# f2838x_cpu1_periph_ac_regs register map
Vendor: Texas Instruments
Peripheral module from a debugger description file (folder C2000).
Address unit: 16 bits
Registers are 32-bit, read-write, no defined reset value unless marked. A register's access mark holds for its fields unless they carry their own. Offsets are as the file gives them; lines under a group give offsets from that group; [hi:lo] are bit positions; {n}, {i} and the like mark numbered series; 'fields as' and 'values as' point back to an identical list; <NAME> marks a mode.

## CPU1_PERIPH_AC_REGS — CPU1 PERIPH AC Registers
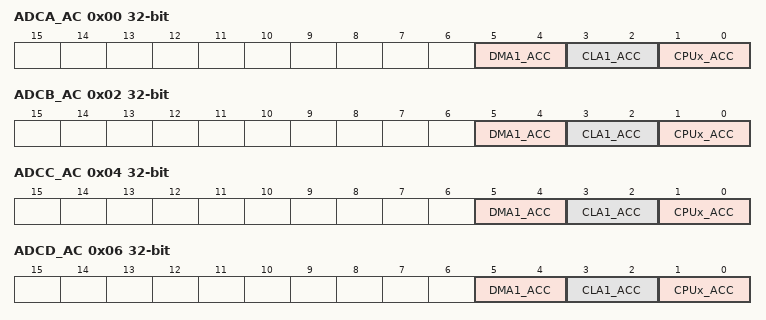
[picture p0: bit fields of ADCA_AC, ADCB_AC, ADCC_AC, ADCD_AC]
0x00 ADCA_AC — ADCA Master Access Control Register
  [5:4] DMA1_ACC — DMA1 Access Conditions to Peripheral
  [3:2] CLA1_ACC — CLA1 Access Conditions to Peripheral
  [1:0] CPUx_ACC — CPU1 Access conditions to peripheral
0x02 ADCB_AC — ADCB Master Access Control Register
  [5:4] DMA1_ACC — DMA1 Access Conditions to Peripheral
  [3:2] CLA1_ACC — CLA1 Access Conditions to Peripheral
  [1:0] CPUx_ACC — CPUx Access conditions to peripheral
0x04 ADCC_AC — ADCC Master Access Control Register
  fields as ADCB_AC
0x06 ADCD_AC — ADCD Master Access Control Register
  fields as ADCB_AC
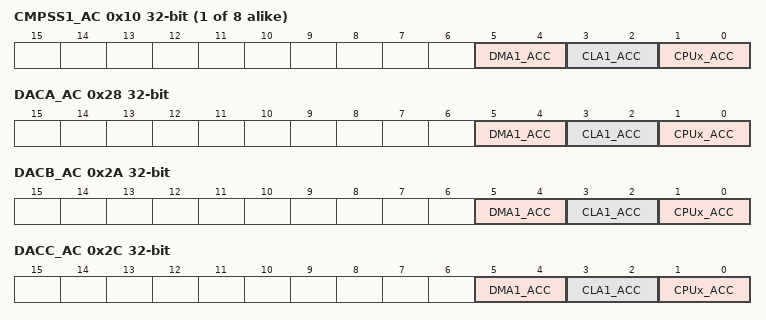
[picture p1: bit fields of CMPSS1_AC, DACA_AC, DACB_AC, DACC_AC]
{0xE+2i} CMPSS{i}_AC (i=1..8) — CMPSS{i} Master Access Control Register
  fields as ADCB_AC
0x28 DACA_AC — DACA Master Access Control Register
  fields as ADCB_AC
0x2A DACB_AC — DACB Master Access Control Register
  fields as ADCB_AC
0x2C DACC_AC — DACC Master Access Control Register
  fields as ADCB_AC
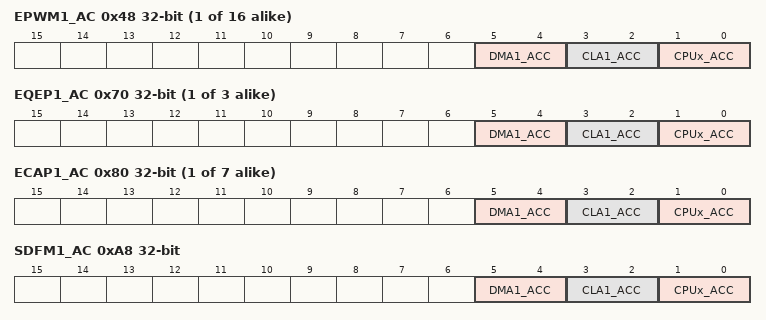
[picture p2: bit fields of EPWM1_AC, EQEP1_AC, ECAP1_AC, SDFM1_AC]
{0x46+2i} EPWM{i}_AC (i=1..16) — EPWM{i} Master Access Control Register
  fields as ADCB_AC
{0x6E+2i} EQEP{i}_AC (i=1..3) — EQEP{i} Master Access Control Register
  fields as ADCB_AC
{0x7E+2i} ECAP{i}_AC (i=1..7) — ECAP{i} Master Access Control Register
  fields as ADCB_AC
0xA8 SDFM1_AC — SDFM1 Master Access Control Register
  fields as ADCB_AC
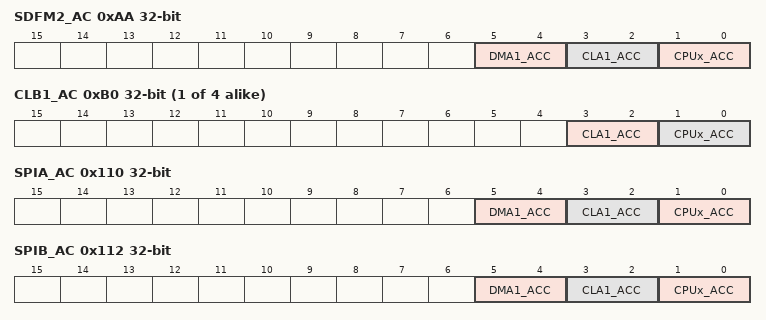
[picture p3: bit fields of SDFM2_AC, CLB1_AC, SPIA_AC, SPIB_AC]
0xAA SDFM2_AC — SDFM2 Master Access Control Register
  fields as ADCB_AC
{0xAE+2i} CLB{i}_AC (i=1..4) — CLB{i} Master Access Control Register
  [3:2] CLA1_ACC — CLA1 Access Conditions to Peripheral
  [1:0] CPUx_ACC — CPUx Access conditions to peripheral
0x110 SPIA_AC — SPIA Master Access Control Register
  fields as ADCB_AC
0x112 SPIB_AC — SPIB Master Access Control Register
  fields as ADCB_AC
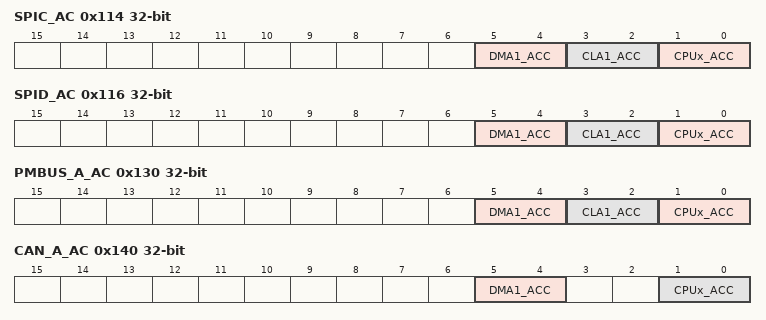
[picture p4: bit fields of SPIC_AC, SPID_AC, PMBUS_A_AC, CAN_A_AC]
0x114 SPIC_AC — SPIC Master Access Control Register
  fields as ADCB_AC
0x116 SPID_AC — SPID Master Access Control Register
  fields as ADCB_AC
0x130 PMBUS_A_AC — PMBUSA Master Access Control Register
  fields as ADCB_AC
0x140 CAN_A_AC — CAN_A Master Access Control Register
  [5:4] DMA1_ACC — DMA1 Access Conditions to Peripheral
  [1:0] CPUx_ACC — CPUx Access conditions to peripheral
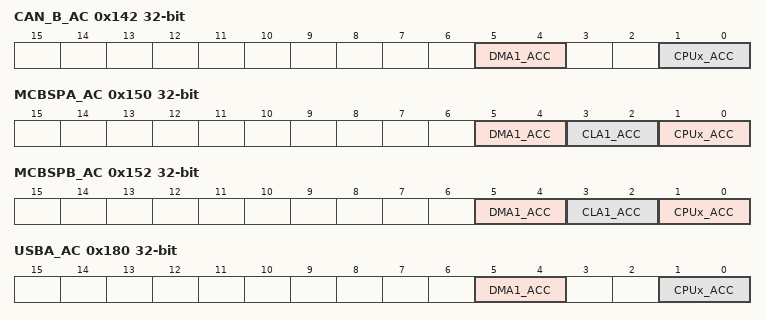
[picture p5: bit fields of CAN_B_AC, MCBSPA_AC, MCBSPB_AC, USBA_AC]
0x142 CAN_B_AC — CAN_B Master Access Control Register
  fields as CAN_A_AC
0x150 MCBSPA_AC — MCBSPA Master Access Control Register
  fields as ADCB_AC
0x152 MCBSPB_AC — MCBSPB Master Access Control Register
  fields as ADCB_AC
0x180 USBA_AC — USBA Master Access Control Register
  fields as CAN_A_AC
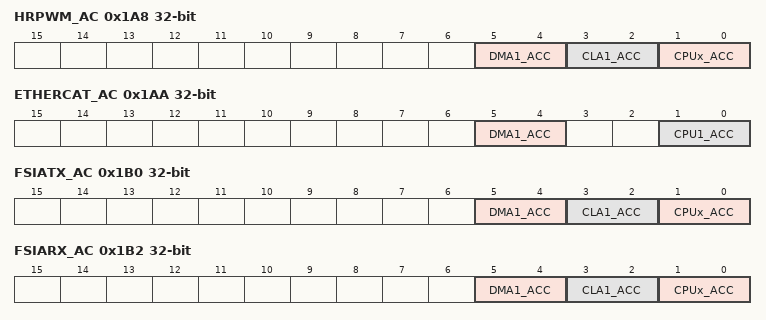
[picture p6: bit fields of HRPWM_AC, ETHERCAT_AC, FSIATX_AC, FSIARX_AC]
0x1A8 HRPWM_AC — HRPWM Master Access Control Register
  fields as ADCB_AC
0x1AA ETHERCAT_AC — ETHERCAT Master Access Control Register
  [5:4] DMA1_ACC — DMA1 Access Conditions to Peripheral
  [1:0] CPU1_ACC — CPU1 Access conditions to peripheral
0x1B0 FSIATX_AC — FSIATX Master Access Control Register
  fields as ADCB_AC
0x1B2 FSIARX_AC — FSIARX Master Access Control Register
  fields as ADCB_AC
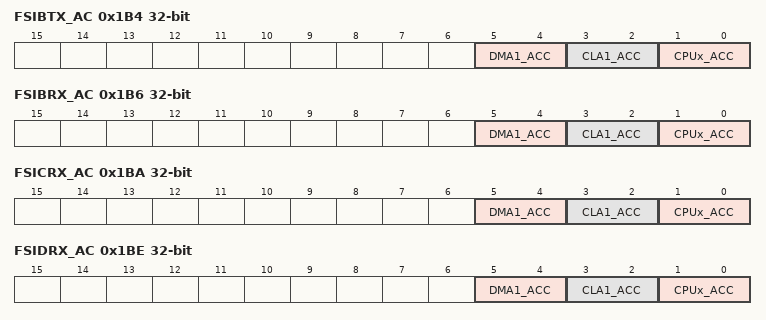
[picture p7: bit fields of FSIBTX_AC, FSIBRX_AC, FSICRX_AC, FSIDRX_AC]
0x1B4 FSIBTX_AC — FSIBTX Master Access Control Register
  fields as ADCB_AC
0x1B6 FSIBRX_AC — FSIBRX Master Access Control Register
  fields as ADCB_AC
0x1BA FSICRX_AC — FSICRX Master Access Control Register
  fields as ADCB_AC
0x1BE FSIDRX_AC — FSIDRX Master Access Control Register
  fields as ADCB_AC
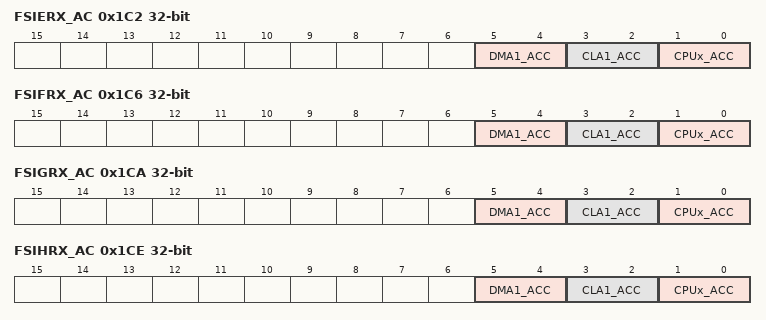
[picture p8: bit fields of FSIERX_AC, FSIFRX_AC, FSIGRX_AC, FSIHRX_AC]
0x1C2 FSIERX_AC — FSIERX Master Access Control Register
  fields as ADCB_AC
0x1C6 FSIFRX_AC — FSIFRX Master Access Control Register
  fields as ADCB_AC
0x1CA FSIGRX_AC — FSIGRX Master Access Control Register
  fields as ADCB_AC
0x1CE FSIHRX_AC — FSIHRX Master Access Control Register
  fields as ADCB_AC
0x1FE PERIPH_AC_LOCK — Lock Register to stop Write access to peripheral Access register.
  [0] LOCK_AC_WR — Lock control for Access control registers write.
